# CM_CORE__GPU register map
Vendor: Texas Instruments
Peripheral module from a debugger description file (folder am572x).
Registers are 32-bit, access per field, reset 0x0 unless marked. A register's access mark holds for its fields unless they carry their own. Offsets are as the file gives them; lines under a group give offsets from that group; [hi:lo] are bit positions; {n}, {i} and the like mark numbered series; 'fields as' and 'values as' point back to an identical list; <NAME> marks a mode.

## CM_CORE__GPU
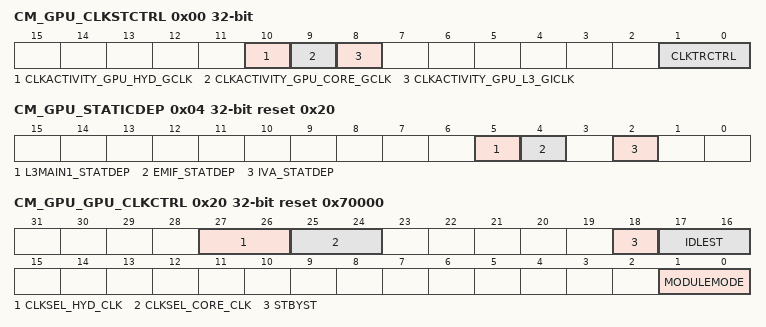
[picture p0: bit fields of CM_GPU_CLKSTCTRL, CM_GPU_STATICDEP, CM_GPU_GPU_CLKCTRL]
0x00 CM_GPU_CLKSTCTRL (reset mask 0xFFFFFFFC) — This register enables the GPU domain power state transition. It controls the HW supervised domain power state transition between ON-ACTIVE and ON-INACTIVE states. It also hold one status bit per clock input of the domain.
  [10] CLKACTIVITY_GPU_HYD_GCLK ro — This field indicates the state of the GPU_HYD_GCLK clock in the domain. [warm reset insensitive]
    0=INACT (Corresponding clock is definitely gated); 1=ACT (Corresponding clock is running or gating/ungating transition is on-going)
  [9] CLKACTIVITY_GPU_CORE_GCLK ro — This field indicates the state of the GPU_CORE_GCLK clock in the domain. [warm reset insensitive]
    values as CLKACTIVITY_GPU_HYD_GCLK
  [8] CLKACTIVITY_GPU_L3_GICLK ro — This field indicates the state of the GPU_L3_GICLK clock in the domain. [warm reset insensitive]
    values as CLKACTIVITY_GPU_HYD_GCLK
  [1:0] CLKTRCTRL rw — Controls the clock state transition of the GPU clock domain.
    0=NO_SLEEP (NO_SLEEP: Sleep transition cannot be initiated. Wakeup transition may however occur.); 1=SW_SLEEP (SW_SLEEP: Start a software forced sleep transition on the domain.); 2=SW_WKUP (SW_WKUP: Start a software forced wake-up transition on the domain.); 3=HW_AUTO (HW_AUTO: Automatic transition is enabled. Sleep and wakeup transition are based upon hardware conditions.)
0x04 CM_GPU_STATICDEP reset 0x20 — This register controls the static domain depedencies from GPU domain towards 'target' domains. It is relevant only for domain having system initiator(s).
  [5] L3MAIN1_STATDEP ro — Static dependency towards L3MAIN1 clock domain
    1=ENABLED (Dependency is enabled)
  [4] EMIF_STATDEP rw — Static dependency towards EMIF clock domain
    0=DISABLED (Dependency is disabled); 1=ENABLED (Dependency is enabled)
  [2] IVA_STATDEP rw — Static dependency towards IVA clock domain
    values as EMIF_STATDEP
0x08 CM_GPU_DYNAMICDEP ro — This register controls the dynamic domain depedencies from GPU domain towards 'target' domains. It is relevant only for domain having OCP master port(s).
  [6] L3MAIN1_DYNDEP — Dynamic dependency towards L3MAIN1 clock domain
    0=DISABLED (Dependency is disabled)
0x20 CM_GPU_GPU_CLKCTRL reset 0x70000 — This register manages the GPU clocks.
  [27:26] CLKSEL_HYD_CLK rw — Select the source of the functional clock
    0=SEL_CORE_GPU_CLK (Selects the CORE_GPU_CLK as the source); 1=SEL_PER_GPU_CLK (Selects the PER_GPU_CLK); 2=SEL_GPU_GCLK (Selects GPU_GCLK)
  [25:24] CLKSEL_CORE_CLK rw — Select the source of the functional clock
    values as CLKSEL_HYD_CLK
  [18] STBYST ro — Module standby status. [warm reset insensitive]
    0=FUNC (Module is functional (not in standby)); 1=STANDBY (Module is in standby)
  [17:16] IDLEST ro — Module idle status. [warm reset insensitive]
    0=FUNC (Module is fully functional, including OCP); 1=TRANS (Module is performing transition: wakeup, or sleep, or sleep abortion); 2=IDLE (Module is in Idle mode (only OCP part). It is functional if using separate functional clock); 3=DISABLE (Module is disabled and cannot be accessed)
  [1:0] MODULEMODE rw — Control the way mandatory clocks are managed.
    0=DISABLED (Module is disabled by SW. Any OCP access to module results in an error, except if resulting from a module wakeup (asynchronous wakeup).); 2=ENABLE (Module is explicitly enabled. Interface clock (if not used for functions) may be gated according to the clock domain state. Functional clocks are guaranteed to stay present. As long as in this configuration, power domain sleep transition cannot happen.)
